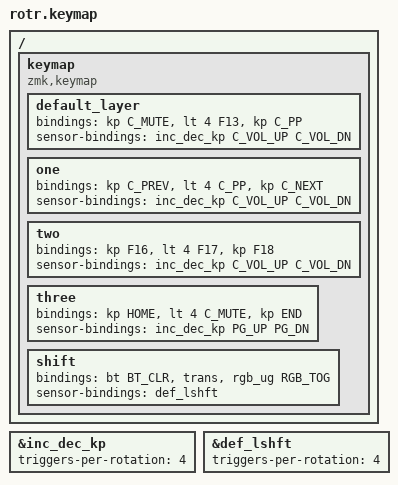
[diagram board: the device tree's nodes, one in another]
#include <behaviors.dtsi>
#include <dt-bindings/zmk/keys.h>
#include <dt-bindings/zmk/rgb.h>
#include <dt-bindings/zmk/bt.h>

&inc_dec_kp {
	triggers-per-rotation = <4>;
};
&def_lshft {
	triggers-per-rotation = <4>;
};

/ {
	keymap {
		compatible = "zmk,keymap";

		default_layer {
			//RED (WORK maybe)
			//MUTE | F13 | PLAY/PAUSE
			bindings = <&kp C_MUTE &lt 4 F13 &kp C_PP>;
			sensor-bindings = <&inc_dec_kp C_VOL_UP C_VOL_DN>;
		};
		one {
			//GREEN (MEDIA)
			//PREV | PLAY/PAUSE | NEXT
			bindings = <&kp C_PREV &lt 4 C_PP &kp C_NEXT>;
			sensor-bindings = <&inc_dec_kp C_VOL_UP C_VOL_DN>;
		};
		two {
			//BLUE (Counter-Strike maybe)
			//F16 | F17 | F18
			bindings = <&kp F16 &lt 4 F17 &kp F18>;
			sensor-bindings = <&inc_dec_kp C_VOL_UP C_VOL_DN>;
		};
		three {
			//YELLOW (Documents)
			//HOME | MUTE | END
			bindings = <&kp HOME &lt 4 C_MUTE &kp END>;
			sensor-bindings = <&inc_dec_kp PG_UP PG_DN>;
		};
		shift {
			//not sure what this is
			bindings = <&bt BT_CLR &trans &rgb_ug RGB_TOG>;
			sensor-bindings = <&def_lshft>;
		};
	};
};
